AUTOSAR XML (schema 3-2-1)
package /seat-heater/Regulator_swc
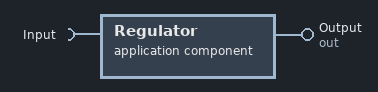
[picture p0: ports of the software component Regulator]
  application software component type Regulator
    provide port Output: provided-interface=out
    require port Input
  internal behavior RegulatorBehavior: compontent=Regulator
    timing event event: start-on-event=runnable1, period=1.0
    runnable runnable1: can-be-invoked-concurrently=true
  swc implementation RegulatorImplementation: behavior=RegulatorBehavior
